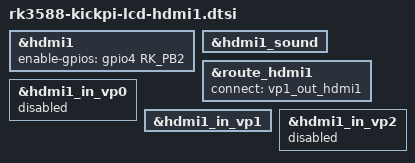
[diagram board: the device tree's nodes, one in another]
&hdmi1 {
	enable-gpios = <&gpio4 RK_PB2 GPIO_ACTIVE_HIGH>;
	status = "okay";
};

&hdmi1_sound {
	status = "okay";
};

&route_hdmi1 {
    connect = <&vp1_out_hdmi1>;
	status = "okay";
};

&hdmi1_in_vp0 {
	status = "disabled";
};

&hdmi1_in_vp1 {
	status = "okay";
};

&hdmi1_in_vp2 {
	status = "disabled";
};
